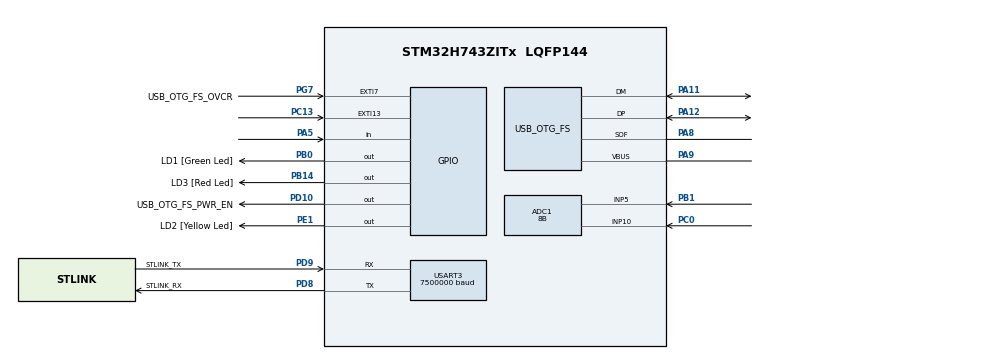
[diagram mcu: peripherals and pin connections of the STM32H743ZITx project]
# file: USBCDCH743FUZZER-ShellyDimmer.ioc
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ADC1.Channel-0\#ChannelRegularConversion=ADC_CHANNEL_10
ADC1.Channel-1\#ChannelRegularConversion=ADC_CHANNEL_5
ADC1.ClockPrescaler=ADC_CLOCK_ASYNC_DIV8
ADC1.ContinuousConvMode=ENABLE
ADC1.ConversionDataManagement=ADC_CONVERSIONDATA_DMA_ONESHOT
ADC1.NbrOfConversion=2
ADC1.NbrOfConversionFlag=1
ADC1.OffsetNumber-0\#ChannelRegularConversion=ADC_OFFSET_NONE
ADC1.OffsetNumber-1\#ChannelRegularConversion=ADC_OFFSET_NONE
ADC1.OffsetSignedSaturation-0\#ChannelRegularConversion=DISABLE
ADC1.OffsetSignedSaturation-1\#ChannelRegularConversion=DISABLE
ADC1.Rank-0\#ChannelRegularConversion=1
ADC1.Rank-1\#ChannelRegularConversion=2
ADC1.Resolution=ADC_RESOLUTION_8B
ADC1.SamplingTime-0\#ChannelRegularConversion=ADC_SAMPLETIME_2CYCLES_5
ADC1.SamplingTime-1\#ChannelRegularConversion=ADC_SAMPLETIME_2CYCLES_5
ADC1.master=1
CRC.InputDataFormat=CRC_INPUTDATA_FORMAT_WORDS
CRC.InputDataInversionMode=CRC_INPUTDATA_INVERSION_WORD
CRC.OutputDataInversionMode=CRC_OUTPUTDATA_INVERSION_ENABLE
Dma.ADC1.0.Direction=DMA_PERIPH_TO_MEMORY
Dma.ADC1.0.EventEnable=DISABLE
Dma.ADC1.0.FIFOMode=DMA_FIFOMODE_DISABLE
Dma.ADC1.0.Instance=DMA1_Stream2
Dma.ADC1.0.MemDataAlignment=DMA_MDATAALIGN_HALFWORD
Dma.ADC1.0.MemInc=DMA_MINC_ENABLE
Dma.ADC1.0.Mode=DMA_CIRCULAR
Dma.ADC1.0.PeriphDataAlignment=DMA_PDATAALIGN_HALFWORD
Dma.ADC1.0.PeriphInc=DMA_PINC_DISABLE
Dma.ADC1.0.Polarity=HAL_DMAMUX_REQ_GEN_RISING
Dma.ADC1.0.Priority=DMA_PRIORITY_LOW
Dma.ADC1.0.RequestNumber=1
Dma.ADC1.0.SignalID=NONE
Dma.ADC1.0.SyncEnable=DISABLE
Dma.ADC1.0.SyncPolarity=HAL_DMAMUX_SYNC_NO_EVENT
Dma.ADC1.0.SyncRequestNumber=1
Dma.ADC1.0.SyncSignalID=NONE
Dma.Request0=ADC1
Mcu.Family=STM32H7
Mcu.Name=STM32H743ZITx
Mcu.Package=LQFP144
NVIC.DMA1_Stream2_IRQn=true\:0\:0\:false\:false\:true\:false\:true\:true
NVIC.EXTI15_10_IRQn=true\:5\:0\:true\:false\:true\:true\:true\:true
NVIC.HASH_RNG_IRQn=true\:0\:0\:false\:false\:true\:true\:true\:true
NVIC.OTG_FS_IRQn=true\:5\:0\:true\:false\:true\:false\:true\:true
NVIC.PriorityGroup=NVIC_PRIORITYGROUP_4
NVIC.TIM16_IRQn=true\:15\:0\:false\:false\:true\:false\:true\:true
NVIC.TIM3_IRQn=true\:5\:0\:true\:false\:true\:true\:true\:true
NVIC.TimeBase=TIM16_IRQn
NVIC.TimeBaseIP=TIM16
PA1.Signal=ETH_REF_CLK
PA11.Mode=Device_Only
PA11.Signal=USB_OTG_FS_DM
PA12.Mode=Device_Only
PA12.Signal=USB_OTG_FS_DP
PA2.Signal=ETH_MDIO
PA5.Signal=GPIO_Input
PA7.Signal=ETH_CRS_DV
PA8.Mode=Activate_SOF_FS
PA8.Signal=USB_OTG_FS_SOF
PA9.Mode=Activate_VBUS
PA9.Signal=USB_OTG_FS_VBUS
PB0.GPIO_Label=LD1 [Green Led]
PB0.Signal=GPIO_Output
PB1.Signal=ADCx_INP5
PB13.Signal=ETH_TXD1
PB14.GPIO_Label=LD3 [Red Led]
PB14.Signal=GPIO_Output
PC0.Signal=ADCx_INP10
PC1.Signal=ETH_MDC
PC13.GPIO_ModeDefaultEXTI=GPIO_MODE_IT_FALLING
PC13.Signal=GPXTI13
PC14-OSC32_IN\ (OSC32_IN).Mode=LSE-External-Oscillator
PC14-OSC32_IN\ (OSC32_IN).Signal=RCC_OSC32_IN
PC15-OSC32_OUT\ (OSC32_OUT).Mode=LSE-External-Oscillator
PC15-OSC32_OUT\ (OSC32_OUT).Signal=RCC_OSC32_OUT
PC4.Signal=ETH_RXD0
PC5.Signal=ETH_RXD1
PD10.GPIO_Label=USB_OTG_FS_PWR_EN
PD10.Signal=GPIO_Output
PD8.GPIO_Label=STLINK_RX
PD8.Mode=Asynchronous
PD8.Signal=USART3_TX
PD9.GPIO_Label=STLINK_TX
PD9.Mode=Asynchronous
PD9.Signal=USART3_RX
PE1.GPIO_Label=LD2 [Yellow Led]
PE1.Signal=GPIO_Output
PG11.Signal=ETH_TX_EN
PG13.Signal=ETH_TXD0
PG7.GPIO_Label=USB_OTG_FS_OVCR
PG7.Signal=GPXTI7
PH0-OSC_IN\ (PH0).Mode=HSE-External-Clock-Source
PH0-OSC_IN\ (PH0).Signal=RCC_OSC_IN
PH1-OSC_OUT\ (PH1).Signal=RCC_OSC_OUT
ProjectManager.HeapSize=0x200
ProjectManager.StackSize=0x400
ProjectManager.TargetToolchain=STM32CubeIDE
RCC.ADCFreq_Value=128000000
RCC.APB1Freq_Value=120000000
RCC.APB2Freq_Value=120000000
RCC.APB3Freq_Value=120000000
RCC.APB4Freq_Value=120000000
RCC.CortexFreq_Value=480000000
RCC.D1PPRE=RCC_APB3_DIV2
RCC.D2PPRE1=RCC_APB1_DIV2
RCC.D2PPRE2=RCC_APB2_DIV2
RCC.D3PPRE=RCC_APB4_DIV2
RCC.DIVM1=1
RCC.DIVM2=1
RCC.DIVN1=120
RCC.DIVN2=64
RCC.DIVP2=4
RCC.HCLKFreq_Value=240000000
RCC.HPRE=RCC_HCLK_DIV2
RCC.HSE_VALUE=8000000
RCC.PLL2FRACN=0
RCC.PLL3FRACN=0
RCC.PLLFRACN=0
RCC.PLLSourceVirtual=RCC_PLLSOURCE_HSE
RCC.PWR_Regulator_Voltage_Scale=PWR_REGULATOR_VOLTAGE_SCALE0
RCC.SYSCLKFreq_VALUE=480000000
RCC.SYSCLKSource=RCC_SYSCLKSOURCE_PLLCLK
RCC.USBCLockSelection=RCC_USBCLKSOURCE_HSI48
RCC.USBFreq_Value=48000000
SH.ADCx_INP10.0=ADC1_INP10,IN10-Single-Ended
SH.ADCx_INP5.0=ADC1_INP5,IN5-Single-Ended
TIM1.AutoReloadPreload=TIM_AUTORELOAD_PRELOAD_ENABLE
TIM1.Channel-Output\ Compare1\ No\ Output=TIM_CHANNEL_1
TIM1.Period=16000
TIM1.Prescaler=4800
TIM1.Pulse-Output\ Compare1\ No\ Output=5
TIM3.AutoReloadPreload=TIM_AUTORELOAD_PRELOAD_ENABLE
TIM3.Channel-Output\ Compare1\ No\ Output=TIM_CHANNEL_1
TIM3.Period=10
TIM3.Prescaler=4800
TIM3.Pulse-Output\ Compare1\ No\ Output=5
USART3.BaudRate=7500000
USART3.VirtualMode-Asynchronous=VM_ASYNC
USB_DEVICE.CLASS_NAME_FS=CDC
USB_DEVICE.VirtualMode-CDC_FS=Cdc
USB_DEVICE.VirtualModeFS=Cdc_FS
USB_OTG_FS.VirtualMode=Device_Only
VP_CRC_VS_CRC.Mode=CRC_Activate
VP_RNG_VS_RNG.Mode=RNG_Activate
VP_SYS_VS_tim16.Mode=TIM16
VP_TIM1_VS_ClockSourceINT.Mode=Internal
VP_TIM1_VS_no_output1.Mode=Output Compare1 No Output
VP_TIM3_VS_ClockSourceINT.Mode=Internal
VP_TIM3_VS_no_output1.Mode=Output Compare1 No Output
VP_USB_DEVICE_VS_USB_DEVICE_CDC_FS.Mode=CDC_FS
board=NUCLEO-H743ZI2

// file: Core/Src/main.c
/* USER CODE BEGIN Header */
/**
  ******************************************************************************
  * @file           : main.c
  * @brief          : Main program body
  ******************************************************************************
  * @attention
  *
  * <h2><center>&copy; Copyright (c) 2021 STMicroelectronics.
  * All rights reserved.</center></h2>
  *
  * This software component is licensed by ST under BSD 3-Clause license,
  * the "License"; You may not use this file except in compliance with the
  * License. You may obtain a copy of the License at:
  *                        opensource.org/licenses/BSD-3-Clause
  *
  ******************************************************************************
  */
/* USER CODE END Header */
#include "main.h"

/* USER CODE BEGIN Includes */
#include "fuzzing.h"
#include "app_main.h"
#include "shelly.h"

//#include "testmodbus.h"
/* USER CODE END Includes */

/* USER CODE BEGIN PTD */

/*
RingBuffer_t inputAFL;
uint32_t inputLength, verify;
volatile bool bRXcomplete;  // variable must be declared as volatile otherwise the compiler may optimize out it
volatile bool bTXcomplete;
volatile uint16_t previousGuard;
uint8_t aflbitmap[AFL_BITMAP_SIZE]; // reserve  8 more bytes for return code and bitmap size
uint8_t aflheader[8];
extern USBD_HandleTypeDef hUsbDeviceFS;
*/
/* USER CODE END PTD */

ADC_HandleTypeDef hadc1;
DMA_HandleTypeDef hdma_adc1;

CRC_HandleTypeDef hcrc;

RNG_HandleTypeDef hrng;

TIM_HandleTypeDef htim1;
TIM_HandleTypeDef htim3;

UART_HandleTypeDef huart3;

void SystemClock_Config(void);
static void MX_GPIO_Init(void);
static void MX_USART3_UART_Init(void);
static void MX_RNG_Init(void);
static void MX_CRC_Init(void);
static void MX_DMA_Init(void);
static void MX_ADC1_Init(void);
static void MX_TIM1_Init(void);
static void MX_TIM3_Init(void);
/* USER CODE BEGIN PFP */
void __io_putchar(uint8_t ch) {
HAL_UART_Transmit(&huart3, &ch, 1, 1);
}
/* USER CODE END PFP */

int main(void)
{
  /* USER CODE BEGIN 1 */

	/* Enable I-Cache */
	SCB_EnableICache();  // we will only use the instruction cache
	/* Enable D-Cache */
	//SCB_EnableDCache();

  /* USER CODE END 1 */

  /* MCU Configuration--------------------------------------------------------*/

  /* Reset of all peripherals, Initializes the Flash interface and the Systick. */
  HAL_Init();

  /* Configure the system clock */
  SystemClock_Config();

  /* USER CODE BEGIN SysInit */
  //inputLength = 0;
  //bRXcomplete = false;

  /* USER CODE END SysInit */

  /* Initialize all configured peripherals */
  MX_GPIO_Init();
  MX_USART3_UART_Init();
  MX_RNG_Init();
  MX_CRC_Init();
  MX_DMA_Init();
  MX_ADC1_Init();
  MX_TIM1_Init();
  MX_TIM3_Init();
  /* USER CODE BEGIN 2 */

  HAL_TIM_Base_Start_IT(&htim3); //initialize the timer that checks ADC conversion
  HAL_TIM_Base_Start_IT(&htim1);

  activateCortexMtrapsUNA();
  // call RTOS initialization routines
  app_main();

 // ASAN_Test();

   // it should never reach beyond this point since the RTOS kernel is in execution at this point

  /* USER CODE END 2 */

  /* Infinite loop */
     while (1)
     {

      }
}

void SystemClock_Config(void)
{
  RCC_OscInitTypeDef RCC_OscInitStruct = {0};
  RCC_ClkInitTypeDef RCC_ClkInitStruct = {0};

  /** Supply configuration update enable
  */
  HAL_PWREx_ConfigSupply(PWR_LDO_SUPPLY);

  /** Configure the main internal regulator output voltage
  */
  __HAL_PWR_VOLTAGESCALING_CONFIG(PWR_REGULATOR_VOLTAGE_SCALE1);

  while(!__HAL_PWR_GET_FLAG(PWR_FLAG_VOSRDY)) {}

  __HAL_RCC_SYSCFG_CLK_ENABLE();
  __HAL_PWR_VOLTAGESCALING_CONFIG(PWR_REGULATOR_VOLTAGE_SCALE0);

  while(!__HAL_PWR_GET_FLAG(PWR_FLAG_VOSRDY)) {}

  /** Macro to configure the PLL clock source
  */
  __HAL_RCC_PLL_PLLSOURCE_CONFIG(RCC_PLLSOURCE_HSE);

  /** Initializes the RCC Oscillators according to the specified parameters
  * in the RCC_OscInitTypeDef structure.
  */
  RCC_OscInitStruct.OscillatorType = RCC_OSCILLATORTYPE_HSI48|RCC_OSCILLATORTYPE_HSE;
  RCC_OscInitStruct.HSEState = RCC_HSE_BYPASS;
  RCC_OscInitStruct.HSI48State = RCC_HSI48_ON;
  RCC_OscInitStruct.PLL.PLLState = RCC_PLL_ON;
  RCC_OscInitStruct.PLL.PLLSource = RCC_PLLSOURCE_HSE;
  RCC_OscInitStruct.PLL.PLLM = 1;
  RCC_OscInitStruct.PLL.PLLN = 120;
  RCC_OscInitStruct.PLL.PLLP = 2;
  RCC_OscInitStruct.PLL.PLLQ = 2;
  RCC_OscInitStruct.PLL.PLLR = 2;
  RCC_OscInitStruct.PLL.PLLRGE = RCC_PLL1VCIRANGE_3;
  RCC_OscInitStruct.PLL.PLLVCOSEL = RCC_PLL1VCOWIDE;
  RCC_OscInitStruct.PLL.PLLFRACN = 0;
  if (HAL_RCC_OscConfig(&RCC_OscInitStruct) != HAL_OK)
  {
    Error_Handler();
  }

  /** Initializes the CPU, AHB and APB buses clocks
  */
  RCC_ClkInitStruct.ClockType = RCC_CLOCKTYPE_HCLK|RCC_CLOCKTYPE_SYSCLK
                              |RCC_CLOCKTYPE_PCLK1|RCC_CLOCKTYPE_PCLK2
                              |RCC_CLOCKTYPE_D3PCLK1|RCC_CLOCKTYPE_D1PCLK1;
  RCC_ClkInitStruct.SYSCLKSource = RCC_SYSCLKSOURCE_PLLCLK;
  RCC_ClkInitStruct.SYSCLKDivider = RCC_SYSCLK_DIV1;
  RCC_ClkInitStruct.AHBCLKDivider = RCC_HCLK_DIV2;
  RCC_ClkInitStruct.APB3CLKDivider = RCC_APB3_DIV2;
  RCC_ClkInitStruct.APB1CLKDivider = RCC_APB1_DIV2;
  RCC_ClkInitStruct.APB2CLKDivider = RCC_APB2_DIV2;
  RCC_ClkInitStruct.APB4CLKDivider = RCC_APB4_DIV2;

  if (HAL_RCC_ClockConfig(&RCC_ClkInitStruct, FLASH_LATENCY_4) != HAL_OK)
  {
    Error_Handler();
  }
}

static void MX_ADC1_Init(void)
{

  ADC_MultiModeTypeDef multimode = {0};
  ADC_ChannelConfTypeDef sConfig = {0};

  /** Common config
  */
  hadc1.Instance = ADC1;
  hadc1.Init.ClockPrescaler = ADC_CLOCK_ASYNC_DIV8;
  hadc1.Init.Resolution = ADC_RESOLUTION_8B;
  hadc1.Init.ScanConvMode = ADC_SCAN_ENABLE;
  hadc1.Init.EOCSelection = ADC_EOC_SINGLE_CONV;
  hadc1.Init.LowPowerAutoWait = DISABLE;
  hadc1.Init.ContinuousConvMode = ENABLE;
  hadc1.Init.NbrOfConversion = 2;
  hadc1.Init.DiscontinuousConvMode = DISABLE;
  hadc1.Init.ExternalTrigConv = ADC_SOFTWARE_START;
  hadc1.Init.ExternalTrigConvEdge = ADC_EXTERNALTRIGCONVEDGE_NONE;
  hadc1.Init.ConversionDataManagement = ADC_CONVERSIONDATA_DMA_ONESHOT;
  hadc1.Init.Overrun = ADC_OVR_DATA_PRESERVED;
  hadc1.Init.LeftBitShift = ADC_LEFTBITSHIFT_NONE;
  hadc1.Init.OversamplingMode = DISABLE;
  if (HAL_ADC_Init(&hadc1) != HAL_OK)
  {
    Error_Handler();
  }

  /** Configure the ADC multi-mode
  */
  multimode.Mode = ADC_MODE_INDEPENDENT;
  if (HAL_ADCEx_MultiModeConfigChannel(&hadc1, &multimode) != HAL_OK)
  {
    Error_Handler();
  }

  /** Configure Regular Channel
  */
  sConfig.Channel = ADC_CHANNEL_10;
  sConfig.Rank = ADC_REGULAR_RANK_1;
  sConfig.SamplingTime = ADC_SAMPLETIME_2CYCLES_5;
  sConfig.SingleDiff = ADC_SINGLE_ENDED;
  sConfig.OffsetNumber = ADC_OFFSET_NONE;
  sConfig.Offset = 0;
  sConfig.OffsetSignedSaturation = DISABLE;
  if (HAL_ADC_ConfigChannel(&hadc1, &sConfig) != HAL_OK)
  {
    Error_Handler();
  }

  /** Configure Regular Channel
  */
  sConfig.Channel = ADC_CHANNEL_5;
  sConfig.Rank = ADC_REGULAR_RANK_2;
  if (HAL_ADC_ConfigChannel(&hadc1, &sConfig) != HAL_OK)
  {
    Error_Handler();
  }

}

static void MX_CRC_Init(void)
{

  hcrc.Instance = CRC;
  hcrc.Init.DefaultPolynomialUse = DEFAULT_POLYNOMIAL_ENABLE;
  hcrc.Init.DefaultInitValueUse = DEFAULT_INIT_VALUE_ENABLE;
  hcrc.Init.InputDataInversionMode = CRC_INPUTDATA_INVERSION_WORD;
  hcrc.Init.OutputDataInversionMode = CRC_OUTPUTDATA_INVERSION_ENABLE;
  hcrc.InputDataFormat = CRC_INPUTDATA_FORMAT_WORDS;
  if (HAL_CRC_Init(&hcrc) != HAL_OK)
  {
    Error_Handler();
  }

}

static void MX_RNG_Init(void)
{

  hrng.Instance = RNG;
  hrng.Init.ClockErrorDetection = RNG_CED_ENABLE;
  if (HAL_RNG_Init(&hrng) != HAL_OK)
  {
    Error_Handler();
  }

}

static void MX_TIM1_Init(void)
{

  TIM_ClockConfigTypeDef sClockSourceConfig = {0};
  TIM_MasterConfigTypeDef sMasterConfig = {0};
  TIM_OC_InitTypeDef sConfigOC = {0};
  TIM_BreakDeadTimeConfigTypeDef sBreakDeadTimeConfig = {0};

  htim1.Instance = TIM1;
  htim1.Init.Prescaler = 4800;
  htim1.Init.CounterMode = TIM_COUNTERMODE_UP;
  htim1.Init.Period = 16000;
  htim1.Init.ClockDivision = TIM_CLOCKDIVISION_DIV1;
  htim1.Init.RepetitionCounter = 0;
  htim1.Init.AutoReloadPreload = TIM_AUTORELOAD_PRELOAD_ENABLE;
  if (HAL_TIM_Base_Init(&htim1) != HAL_OK)
  {
    Error_Handler();
  }
  sClockSourceConfig.ClockSource = TIM_CLOCKSOURCE_INTERNAL;
  if (HAL_TIM_ConfigClockSource(&htim1, &sClockSourceConfig) != HAL_OK)
  {
    Error_Handler();
  }
  if (HAL_TIM_OC_Init(&htim1) != HAL_OK)
  {
    Error_Handler();
  }
  sMasterConfig.MasterOutputTrigger = TIM_TRGO_RESET;
  sMasterConfig.MasterOutputTrigger2 = TIM_TRGO2_RESET;
  sMasterConfig.MasterSlaveMode = TIM_MASTERSLAVEMODE_DISABLE;
  if (HAL_TIMEx_MasterConfigSynchronization(&htim1, &sMasterConfig) != HAL_OK)
  {
    Error_Handler();
  }
  sConfigOC.OCMode = TIM_OCMODE_TIMING;
  sConfigOC.Pulse = 5;
  sConfigOC.OCPolarity = TIM_OCPOLARITY_HIGH;
  sConfigOC.OCNPolarity = TIM_OCNPOLARITY_HIGH;
  sConfigOC.OCFastMode = TIM_OCFAST_DISABLE;
  sConfigOC.OCIdleState = TIM_OCIDLESTATE_RESET;
  sConfigOC.OCNIdleState = TIM_OCNIDLESTATE_RESET;
  if (HAL_TIM_OC_ConfigChannel(&htim1, &sConfigOC, TIM_CHANNEL_1) != HAL_OK)
  {
    Error_Handler();
  }
  sBreakDeadTimeConfig.OffStateRunMode = TIM_OSSR_DISABLE;
  sBreakDeadTimeConfig.OffStateIDLEMode = TIM_OSSI_DISABLE;
  sBreakDeadTimeConfig.LockLevel = TIM_LOCKLEVEL_OFF;
  sBreakDeadTimeConfig.DeadTime = 0;
  sBreakDeadTimeConfig.BreakState = TIM_BREAK_DISABLE;
  sBreakDeadTimeConfig.BreakPolarity = TIM_BREAKPOLARITY_HIGH;
  sBreakDeadTimeConfig.BreakFilter = 0;
  sBreakDeadTimeConfig.Break2State = TIM_BREAK2_DISABLE;
  sBreakDeadTimeConfig.Break2Polarity = TIM_BREAK2POLARITY_HIGH;
  sBreakDeadTimeConfig.Break2Filter = 0;
  sBreakDeadTimeConfig.AutomaticOutput = TIM_AUTOMATICOUTPUT_DISABLE;
  if (HAL_TIMEx_ConfigBreakDeadTime(&htim1, &sBreakDeadTimeConfig) != HAL_OK)
  {
    Error_Handler();
  }

}

static void MX_TIM3_Init(void)
{

  TIM_ClockConfigTypeDef sClockSourceConfig = {0};
  TIM_MasterConfigTypeDef sMasterConfig = {0};
  TIM_OC_InitTypeDef sConfigOC = {0};

  htim3.Instance = TIM3;
  htim3.Init.Prescaler = 4800;
  htim3.Init.CounterMode = TIM_COUNTERMODE_UP;
  htim3.Init.Period = 10;
  htim3.Init.ClockDivision = TIM_CLOCKDIVISION_DIV1;
  htim3.Init.AutoReloadPreload = TIM_AUTORELOAD_PRELOAD_ENABLE;
  if (HAL_TIM_Base_Init(&htim3) != HAL_OK)
  {
    Error_Handler();
  }
  sClockSourceConfig.ClockSource = TIM_CLOCKSOURCE_INTERNAL;
  if (HAL_TIM_ConfigClockSource(&htim3, &sClockSourceConfig) != HAL_OK)
  {
    Error_Handler();
  }
  if (HAL_TIM_OC_Init(&htim3) != HAL_OK)
  {
    Error_Handler();
  }
  sMasterConfig.MasterOutputTrigger = TIM_TRGO_RESET;
  sMasterConfig.MasterSlaveMode = TIM_MASTERSLAVEMODE_DISABLE;
  if (HAL_TIMEx_MasterConfigSynchronization(&htim3, &sMasterConfig) != HAL_OK)
  {
    Error_Handler();
  }
  sConfigOC.OCMode = TIM_OCMODE_TIMING;
  sConfigOC.Pulse = 5;
  sConfigOC.OCPolarity = TIM_OCPOLARITY_HIGH;
  sConfigOC.OCFastMode = TIM_OCFAST_DISABLE;
  if (HAL_TIM_OC_ConfigChannel(&htim3, &sConfigOC, TIM_CHANNEL_1) != HAL_OK)
  {
    Error_Handler();
  }

}

static void MX_USART3_UART_Init(void)
{

  huart3.Instance = USART3;
  huart3.Init.BaudRate = 7500000;
  huart3.Init.WordLength = UART_WORDLENGTH_8B;
  huart3.Init.StopBits = UART_STOPBITS_1;
  huart3.Init.Parity = UART_PARITY_NONE;
  huart3.Init.Mode = UART_MODE_TX_RX;
  huart3.Init.HwFlowCtl = UART_HWCONTROL_NONE;
  huart3.Init.OverSampling = UART_OVERSAMPLING_16;
  huart3.Init.OneBitSampling = UART_ONE_BIT_SAMPLE_DISABLE;
  huart3.Init.ClockPrescaler = UART_PRESCALER_DIV1;
  huart3.AdvancedInit.AdvFeatureInit = UART_ADVFEATURE_NO_INIT;
  if (HAL_UART_Init(&huart3) != HAL_OK)
  {
    Error_Handler();
  }
  if (HAL_UARTEx_SetTxFifoThreshold(&huart3, UART_TXFIFO_THRESHOLD_1_8) != HAL_OK)
  {
    Error_Handler();
  }
  if (HAL_UARTEx_SetRxFifoThreshold(&huart3, UART_RXFIFO_THRESHOLD_1_8) != HAL_OK)
  {
    Error_Handler();
  }
  if (HAL_UARTEx_DisableFifoMode(&huart3) != HAL_OK)
  {
    Error_Handler();
  }

}

static void MX_DMA_Init(void)
{

  /* DMA controller clock enable */
  __HAL_RCC_DMA1_CLK_ENABLE();

  /* DMA interrupt init */
  /* DMA1_Stream2_IRQn interrupt configuration */
  HAL_NVIC_SetPriority(DMA1_Stream2_IRQn, 0, 0);
  HAL_NVIC_EnableIRQ(DMA1_Stream2_IRQn);

}

static void MX_GPIO_Init(void)
{
  GPIO_InitTypeDef GPIO_InitStruct = {0};

  /* GPIO Ports Clock Enable */
  __HAL_RCC_GPIOC_CLK_ENABLE();
  __HAL_RCC_GPIOH_CLK_ENABLE();
  __HAL_RCC_GPIOA_CLK_ENABLE();
  __HAL_RCC_GPIOB_CLK_ENABLE();
  __HAL_RCC_GPIOD_CLK_ENABLE();
  __HAL_RCC_GPIOG_CLK_ENABLE();
  __HAL_RCC_GPIOE_CLK_ENABLE();

  /*Configure GPIO pin Output Level */
  HAL_GPIO_WritePin(GPIOB, LD1_Pin|LD3_Pin, GPIO_PIN_RESET);

  /*Configure GPIO pin Output Level */
  HAL_GPIO_WritePin(USB_OTG_FS_PWR_EN_GPIO_Port, USB_OTG_FS_PWR_EN_Pin, GPIO_PIN_RESET);

  /*Configure GPIO pin Output Level */
  HAL_GPIO_WritePin(LD2_GPIO_Port, LD2_Pin, GPIO_PIN_RESET);

  /*Configure GPIO pin : PC13 */
  GPIO_InitStruct.Pin = GPIO_PIN_13;
  GPIO_InitStruct.Mode = GPIO_MODE_IT_FALLING;
  GPIO_InitStruct.Pull = GPIO_NOPULL;
  HAL_GPIO_Init(GPIOC, &GPIO_InitStruct);

  /*Configure GPIO pins : PC1 PC4 PC5 */
  GPIO_InitStruct.Pin = GPIO_PIN_1|GPIO_PIN_4|GPIO_PIN_5;
  GPIO_InitStruct.Mode = GPIO_MODE_AF_PP;
  GPIO_InitStruct.Pull = GPIO_NOPULL;
  GPIO_InitStruct.Speed = GPIO_SPEED_FREQ_LOW;
  GPIO_InitStruct.Alternate = GPIO_AF11_ETH;
  HAL_GPIO_Init(GPIOC, &GPIO_InitStruct);

  /*Configure GPIO pins : PA1 PA2 PA7 */
  GPIO_InitStruct.Pin = GPIO_PIN_1|GPIO_PIN_2|GPIO_PIN_7;
  GPIO_InitStruct.Mode = GPIO_MODE_AF_PP;
  GPIO_InitStruct.Pull = GPIO_NOPULL;
  GPIO_InitStruct.Speed = GPIO_SPEED_FREQ_LOW;
  GPIO_InitStruct.Alternate = GPIO_AF11_ETH;
  HAL_GPIO_Init(GPIOA, &GPIO_InitStruct);

  /*Configure GPIO pin : PA5 */
  GPIO_InitStruct.Pin = GPIO_PIN_5;
  GPIO_InitStruct.Mode = GPIO_MODE_INPUT;
  GPIO_InitStruct.Pull = GPIO_NOPULL;
  HAL_GPIO_Init(GPIOA, &GPIO_InitStruct);

  /*Configure GPIO pins : LD1_Pin LD3_Pin */
  GPIO_InitStruct.Pin = LD1_Pin|LD3_Pin;
  GPIO_InitStruct.Mode = GPIO_MODE_OUTPUT_PP;
  GPIO_InitStruct.Pull = GPIO_NOPULL;
  GPIO_InitStruct.Speed = GPIO_SPEED_FREQ_LOW;
  HAL_GPIO_Init(GPIOB, &GPIO_InitStruct);

  /*Configure GPIO pin : PB13 */
  GPIO_InitStruct.Pin = GPIO_PIN_13;
  GPIO_InitStruct.Mode = GPIO_MODE_AF_PP;
  GPIO_InitStruct.Pull = GPIO_NOPULL;
  GPIO_InitStruct.Speed = GPIO_SPEED_FREQ_LOW;
  GPIO_InitStruct.Alternate = GPIO_AF11_ETH;
  HAL_GPIO_Init(GPIOB, &GPIO_InitStruct);

  /*Configure GPIO pin : USB_OTG_FS_PWR_EN_Pin */
  GPIO_InitStruct.Pin = USB_OTG_FS_PWR_EN_Pin;
  GPIO_InitStruct.Mode = GPIO_MODE_OUTPUT_PP;
  GPIO_InitStruct.Pull = GPIO_NOPULL;
  GPIO_InitStruct.Speed = GPIO_SPEED_FREQ_LOW;
  HAL_GPIO_Init(USB_OTG_FS_PWR_EN_GPIO_Port, &GPIO_InitStruct);

  /*Configure GPIO pin : USB_OTG_FS_OVCR_Pin */
  GPIO_InitStruct.Pin = USB_OTG_FS_OVCR_Pin;
  GPIO_InitStruct.Mode = GPIO_MODE_IT_RISING;
  GPIO_InitStruct.Pull = GPIO_NOPULL;
  HAL_GPIO_Init(USB_OTG_FS_OVCR_GPIO_Port, &GPIO_InitStruct);

  /*Configure GPIO pins : PG11 PG13 */
  GPIO_InitStruct.Pin = GPIO_PIN_11|GPIO_PIN_13;
  GPIO_InitStruct.Mode = GPIO_MODE_AF_PP;
  GPIO_InitStruct.Pull = GPIO_NOPULL;
  GPIO_InitStruct.Speed = GPIO_SPEED_FREQ_LOW;
  GPIO_InitStruct.Alternate = GPIO_AF11_ETH;
  HAL_GPIO_Init(GPIOG, &GPIO_InitStruct);

  /*Configure GPIO pin : LD2_Pin */
  GPIO_InitStruct.Pin = LD2_Pin;
  GPIO_InitStruct.Mode = GPIO_MODE_OUTPUT_PP;
  GPIO_InitStruct.Pull = GPIO_NOPULL;
  GPIO_InitStruct.Speed = GPIO_SPEED_FREQ_LOW;
  HAL_GPIO_Init(LD2_GPIO_Port, &GPIO_InitStruct);

  /* EXTI interrupt init*/
  HAL_NVIC_SetPriority(EXTI15_10_IRQn, 5, 0);
  HAL_NVIC_EnableIRQ(EXTI15_10_IRQn);

}

void HAL_TIM_PeriodElapsedCallback(TIM_HandleTypeDef *htim)
{
  if (htim->Instance == TIM16) {
    HAL_IncTick();
  }
  /* USER CODE BEGIN Callback 1 */
  if (htim == &htim3)
   {
 	  tim3_isr();
   }
  /* USER CODE END Callback 1 */
}

void Error_Handler(void)
{
  __disable_irq();
  while (1)
  {
  }
}
